VERSION ""

NS_ :

BS_:

BU_: VCM LBC INV TEST

BO_ 282 VCM_Shift: 8 VCM
 SG_ ShiftPosition : 7|4@0+ (1,0) [0|15] "" LBC
 SG_ EcoMode : 12|1@1+ (1,0) [0|1] "" LBC

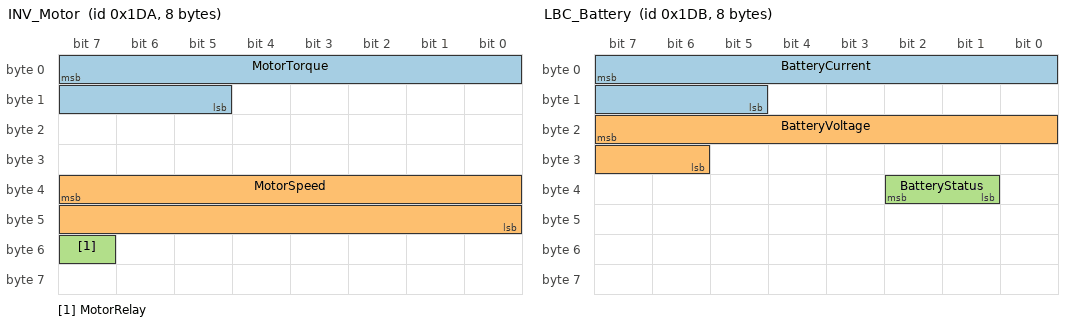
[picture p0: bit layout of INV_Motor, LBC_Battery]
BO_ 474 INV_Motor: 8 INV
 SG_ MotorTorque : 7|11@0- (0.5,0) [-512|511.5] "Nm" VCM
 SG_ MotorSpeed : 39|16@0- (0.5,0) [-16384|16383.5] "rpm" VCM
 SG_ MotorRelay : 55|1@0+ (1,0) [0|1] "" VCM

BO_ 475 LBC_Battery: 8 LBC
 SG_ BatteryCurrent : 7|11@0- (0.5,0) [-512|511.5] "A" VCM
 SG_ BatteryVoltage : 23|10@0+ (0.5,0) [0|511.5] "V" VCM
 SG_ BatteryStatus : 33|2@1+ (1,0) [0|3] "" VCM

BO_ 1118 VCM_Gear: 1 VCM
 SG_ Gear : 0|4@1+ (1,0) [0|15] "" INV

BO_ 1291 VCM_HVAC: 7 VCM
 SG_ HvacPower : 31|16@0+ (0.1,0) [0|6553.5] "kW" LBC
 SG_ CabinTemp : 48|8@1- (0.5,20) [-44|83.5] "degC" LBC

BO_ 1371 LBC_SOC: 8 LBC
 SG_ SOC : 0|10@1+ (0.1,0) [0|102.3] "%" VCM

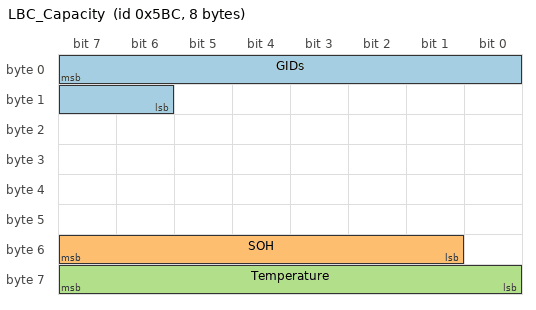
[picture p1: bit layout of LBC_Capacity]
BO_ 1468 LBC_Capacity: 8 LBC
 SG_ GIDs : 7|10@0+ (1,0) [0|1023] "" VCM
 SG_ SOH : 55|7@0+ (1,0) [0|127] "%" VCM
 SG_ Temperature : 63|8@0+ (1,-40) [-40|215] "degC" VCM

BO_ 1472 LBC_Temps: 8 LBC
 SG_ TempMux M : 0|2@1+ (1,0) [0|3] "" VCM
 SG_ TempMax m0 : 15|8@0+ (1,-40) [-40|215] "degC" VCM
 SG_ TempMin m1 : 15|8@0+ (1,-40) [-40|215] "degC" VCM

BO_ 1801 TEST_FD12: 12 TEST
 SG_ Last12 : 88|8@1+ (1,0) [0|255] "" VCM
 SG_ MotoAcross : 71|16@0+ (1,0) [0|65535] "" VCM

BO_ 1807 TEST_FD64: 64 TEST
 SG_ Scaled : 88|12@1- (0.25,-10) [-522|501.75] "V" VCM
 SG_ Float32 : 160|32@1- (1,0) [-1e+38|1e+38] "" VCM
 SG_ Double64 : 256|64@1- (1,0) [-1e+300|1e+300] "" VCM
 SG_ Byte40Word : 320|16@1+ (1,0) [0|65535] "" VCM
 SG_ Wide64 : 384|64@1- (1,0) [-9.22337203685478e+18|9.22337203685478e+18] "" VCM
 SG_ Tail32 : 487|32@0+ (1,0) [0|4294967295] "" VCM
 SG_ HighBits : 500|7@1+ (1,0) [0|127] "" VCM

BO_ 2166572406 TEST_FDX64: 64 TEST
 SG_ ExtMoto : 7|16@0+ (1,0) [0|65535] "" VCM
 SG_ ExtLast : 504|8@1+ (1,0) [0|255] "" VCM
 SG_ ExtU64 : 64|64@1+ (1,0) [0|1.84467440737096e+19] "" VCM

CM_ BO_ 475 "Battery current, voltage and status";
CM_ SG_ 1807 HighBits "A signal past bit 63, across bytes 62 and 63";
BA_DEF_ BO_ "GenMsgBackgroundColor" STRING ;
BA_DEF_ BO_ "GenMsgForegroundColor" STRING ;
BA_DEF_ BO_ "VFrameFormat" ENUM "StandardCAN","ExtendedCAN","reserved","J1939PG","reserved","reserved","reserved","reserved","reserved","reserved","reserved","reserved","reserved","reserved","StandardCAN_FD","ExtendedCAN_FD";
BA_DEF_ BO_ "CANFD_BRS" ENUM "0","1";
BA_DEF_DEF_ "GenMsgBackgroundColor" "#ffffff";
BA_DEF_DEF_ "GenMsgForegroundColor" "#000000";
BA_DEF_DEF_ "VFrameFormat" "StandardCAN";
BA_DEF_DEF_ "CANFD_BRS" "1";
BA_ "GenMsgBackgroundColor" BO_ 475 "#ffe0e0";
BA_ "GenMsgForegroundColor" BO_ 474 "#0000ff";
BA_ "GenMsgBackgroundColor" BO_ 1371 "#203040";
BA_ "GenMsgForegroundColor" BO_ 1371 "#ffffff";
BA_ "VFrameFormat" BO_ 1801 14;
BA_ "VFrameFormat" BO_ 1807 14;
BA_ "VFrameFormat" BO_ 2166572406 15;
VAL_ 282 ShiftPosition 1 "Park" 2 "Reverse" 3 "Neutral" 4 "Drive" 5 "Eco" ;
VAL_ 475 BatteryStatus 0 "Normal" 1 "Charging" 2 "Fault" 3 "Unknown" ;
SIG_VALTYPE_ 1807 Float32 : 1;
SIG_VALTYPE_ 1807 Double64 : 2;
